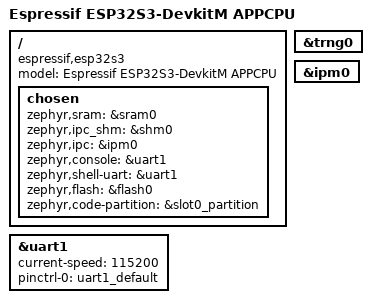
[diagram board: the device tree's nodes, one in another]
/*
 * Copyright (c) 2023 Espressif Systems (Shanghai) Co., Ltd.
 *
 * SPDX-License-Identifier: Apache-2.0
 */
/dts-v1/;

#include <espressif/esp32s3/esp32s3_appcpu.dtsi>
#include <espressif/partitions_0x0_amp.dtsi>
#include "esp32s3_devkitm-pinctrl.dtsi"

/ {
	model = "Espressif ESP32S3-DevkitM APPCPU";
	compatible = "espressif,esp32s3";

	chosen {
		zephyr,sram = &sram0;
		zephyr,ipc_shm = &shm0;
		zephyr,ipc = &ipm0;
		zephyr,console = &uart1;
		zephyr,shell-uart = &uart1;
		zephyr,flash = &flash0;
		zephyr,code-partition = &slot0_partition;
	};
};

&trng0 {
	status = "okay";
};

&ipm0 {
	status = "okay";
};

&uart1 {
	status = "okay";
	current-speed = <115200>;
	pinctrl-0 = <&uart1_default>;
	pinctrl-names = "default";
};
